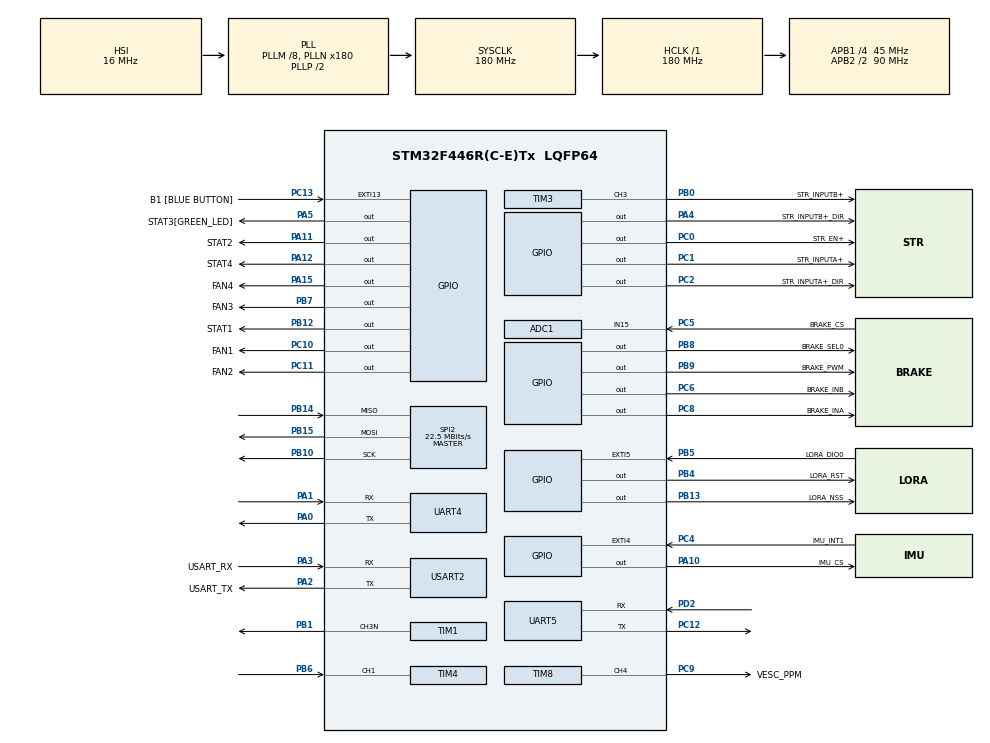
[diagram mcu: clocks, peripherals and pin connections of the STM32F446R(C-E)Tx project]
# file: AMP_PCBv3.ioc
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ADC1.Channel-0\#ChannelRegularConversion=ADC_CHANNEL_15
ADC1.NbrOfConversionFlag=1
ADC1.Rank-0\#ChannelRegularConversion=1
ADC1.SamplingTime-0\#ChannelRegularConversion=ADC_SAMPLETIME_3CYCLES
ADC1.master=1
Dma.Request0=USART2_TX
Dma.Request1=UART4_TX
Dma.Request2=UART4_RX
Dma.Request3=USART2_RX
Dma.Request4=TIM1_CH3
Dma.TIM1_CH3.4.Direction=DMA_MEMORY_TO_PERIPH
Dma.TIM1_CH3.4.FIFOMode=DMA_FIFOMODE_DISABLE
Dma.TIM1_CH3.4.Instance=DMA2_Stream6
Dma.TIM1_CH3.4.MemDataAlignment=DMA_MDATAALIGN_HALFWORD
Dma.TIM1_CH3.4.MemInc=DMA_MINC_ENABLE
Dma.TIM1_CH3.4.Mode=DMA_CIRCULAR
Dma.TIM1_CH3.4.PeriphDataAlignment=DMA_PDATAALIGN_HALFWORD
Dma.TIM1_CH3.4.PeriphInc=DMA_PINC_DISABLE
Dma.TIM1_CH3.4.Priority=DMA_PRIORITY_LOW
Dma.UART4_RX.2.Direction=DMA_PERIPH_TO_MEMORY
Dma.UART4_RX.2.FIFOMode=DMA_FIFOMODE_DISABLE
Dma.UART4_RX.2.Instance=DMA1_Stream2
Dma.UART4_RX.2.MemDataAlignment=DMA_MDATAALIGN_BYTE
Dma.UART4_RX.2.MemInc=DMA_MINC_ENABLE
Dma.UART4_RX.2.Mode=DMA_NORMAL
Dma.UART4_RX.2.PeriphDataAlignment=DMA_PDATAALIGN_BYTE
Dma.UART4_RX.2.PeriphInc=DMA_PINC_DISABLE
Dma.UART4_RX.2.Priority=DMA_PRIORITY_LOW
Dma.UART4_TX.1.Direction=DMA_MEMORY_TO_PERIPH
Dma.UART4_TX.1.FIFOMode=DMA_FIFOMODE_DISABLE
Dma.UART4_TX.1.Instance=DMA1_Stream4
Dma.UART4_TX.1.MemDataAlignment=DMA_MDATAALIGN_BYTE
Dma.UART4_TX.1.MemInc=DMA_MINC_ENABLE
Dma.UART4_TX.1.Mode=DMA_NORMAL
Dma.UART4_TX.1.PeriphDataAlignment=DMA_PDATAALIGN_BYTE
Dma.UART4_TX.1.PeriphInc=DMA_PINC_DISABLE
Dma.UART4_TX.1.Priority=DMA_PRIORITY_LOW
Dma.USART2_RX.3.Direction=DMA_PERIPH_TO_MEMORY
Dma.USART2_RX.3.FIFOMode=DMA_FIFOMODE_DISABLE
Dma.USART2_RX.3.Instance=DMA1_Stream5
Dma.USART2_RX.3.MemDataAlignment=DMA_MDATAALIGN_BYTE
Dma.USART2_RX.3.MemInc=DMA_MINC_ENABLE
Dma.USART2_RX.3.Mode=DMA_NORMAL
Dma.USART2_RX.3.PeriphDataAlignment=DMA_PDATAALIGN_BYTE
Dma.USART2_RX.3.PeriphInc=DMA_PINC_DISABLE
Dma.USART2_RX.3.Priority=DMA_PRIORITY_LOW
Dma.USART2_TX.0.Direction=DMA_MEMORY_TO_PERIPH
Dma.USART2_TX.0.FIFOMode=DMA_FIFOMODE_DISABLE
Dma.USART2_TX.0.Instance=DMA1_Stream6
Dma.USART2_TX.0.MemDataAlignment=DMA_MDATAALIGN_BYTE
Dma.USART2_TX.0.MemInc=DMA_MINC_ENABLE
Dma.USART2_TX.0.Mode=DMA_NORMAL
Dma.USART2_TX.0.PeriphDataAlignment=DMA_PDATAALIGN_BYTE
Dma.USART2_TX.0.PeriphInc=DMA_PINC_DISABLE
Dma.USART2_TX.0.Priority=DMA_PRIORITY_LOW
Mcu.Family=STM32F4
Mcu.Name=STM32F446R(C-E)Tx
Mcu.Package=LQFP64
NVIC.DMA1_Stream2_IRQn=true\:0\:0\:false\:false\:true\:false\:true\:true
NVIC.DMA1_Stream4_IRQn=true\:0\:0\:false\:false\:true\:false\:true\:true
NVIC.DMA1_Stream5_IRQn=true\:0\:0\:false\:false\:true\:false\:true\:true
NVIC.DMA1_Stream6_IRQn=true\:0\:0\:false\:false\:true\:false\:true\:true
NVIC.DMA2_Stream6_IRQn=true\:0\:0\:false\:false\:true\:false\:true\:true
NVIC.EXTI4_IRQn=true\:0\:0\:false\:false\:true\:true\:true\:true
NVIC.EXTI9_5_IRQn=true\:0\:0\:false\:false\:true\:true\:true\:true
NVIC.PriorityGroup=NVIC_PRIORITYGROUP_0
NVIC.TIM6_DAC_IRQn=true\:0\:0\:false\:false\:true\:true\:true\:true
NVIC.TIM7_IRQn=true\:0\:0\:false\:false\:true\:true\:true\:true
NVIC.UART4_IRQn=true\:0\:0\:false\:false\:true\:true\:true\:true
NVIC.USART2_IRQn=true\:0\:0\:false\:false\:true\:true\:true\:true
PA0-WKUP.Mode=Asynchronous
PA0-WKUP.Signal=UART4_TX
PA1.Mode=Asynchronous
PA1.Signal=UART4_RX
PA10.GPIO_Label=IMU_CS
PA10.Signal=GPIO_Output
PA11.GPIO_Label=STAT2
PA11.Signal=GPIO_Output
PA12.GPIO_Label=STAT4
PA12.Signal=GPIO_Output
PA13.GPIO_Label=TMS
PA13.Mode=Serial_Wire
PA13.Signal=SYS_JTMS-SWDIO
PA14.GPIO_Label=TCK
PA14.Mode=Serial_Wire
PA14.Signal=SYS_JTCK-SWCLK
PA15.GPIO_Label=FAN4
PA15.Signal=GPIO_Output
PA2.GPIO_Label=USART_TX
PA2.Mode=Asynchronous
PA2.Signal=USART2_TX
PA3.GPIO_Label=USART_RX
PA3.Mode=Asynchronous
PA3.Signal=USART2_RX
PA4.GPIO_Label=STR_INPUTB+_DIR
PA4.Signal=GPIO_Output
PA5.GPIO_Label=STAT3[GREEN_LED]
PA5.Signal=GPIO_Output
PB0.GPIO_Label=STR_INPUTB+
PB0.Signal=S_TIM3_CH3
PB1.Mode=PWM Generation3 CH3N
PB1.Signal=TIM1_CH3N
PB10.Mode=Full_Duplex_Master
PB10.Signal=SPI2_SCK
PB12.GPIO_Label=STAT1
PB12.Signal=GPIO_Output
PB13.GPIO_Label=LORA_NSS
PB13.Signal=GPIO_Output
PB14.Mode=Full_Duplex_Master
PB14.Signal=SPI2_MISO
PB15.Mode=Full_Duplex_Master
PB15.Signal=SPI2_MOSI
PB3.GPIO_Label=SWO
PB3.Signal=SYS_JTDO-SWO
PB4.GPIO_Label=LORA_RST
PB4.Signal=GPIO_Output
PB5.GPIO_Label=LORA_DIO0
PB5.Signal=GPXTI5
PB6.Signal=S_TIM4_CH1
PB7.GPIO_Label=FAN3
PB7.Signal=GPIO_Output
PB8.GPIO_Label=BRAKE_SEL0
PB8.Signal=GPIO_Output
PB9.GPIO_Label=BRAKE_PWM
PB9.Signal=GPIO_Output
PC0.GPIO_Label=STR_EN+
PC0.Signal=GPIO_Output
PC1.GPIO_Label=STR_INPUTA+
PC1.Signal=GPIO_Output
PC10.GPIO_Label=FAN1
PC10.Signal=GPIO_Output
PC11.GPIO_Label=FAN2
PC11.Signal=GPIO_Output
PC12.Mode=Asynchronous
PC12.Signal=UART5_TX
PC13.GPIO_Label=B1 [BLUE BUTTON]
PC13.GPIO_ModeDefaultEXTI=GPIO_MODE_IT_FALLING
PC13.Signal=GPXTI13
PC14-OSC32_IN.Mode=LSE-External-Oscillator
PC14-OSC32_IN.Signal=RCC_OSC32_IN
PC15-OSC32_OUT.Mode=LSE-External-Oscillator
PC15-OSC32_OUT.Signal=RCC_OSC32_OUT
PC2.GPIO_Label=STR_INPUTA+_DIR
PC2.Signal=GPIO_Output
PC4.GPIO_Label=IMU_INT1
PC4.Signal=GPXTI4
PC5.GPIO_Label=BRAKE_CS
PC5.Signal=ADCx_IN15
PC6.GPIO_Label=BRAKE_INB
PC6.Signal=GPIO_Output
PC8.GPIO_Label=BRAKE_INA
PC8.Signal=GPIO_Output
PC9.GPIO_Label=VESC_PPM
PC9.Signal=S_TIM8_CH4
PD2.Mode=Asynchronous
PD2.Signal=UART5_RX
PH0-OSC_IN.Mode=HSE-External-Oscillator
PH0-OSC_IN.Signal=RCC_OSC_IN
PH1-OSC_OUT.Mode=HSE-External-Oscillator
PH1-OSC_OUT.Signal=RCC_OSC_OUT
ProjectManager.HeapSize=0x200
ProjectManager.StackSize=0x400
ProjectManager.TargetToolchain=STM32CubeIDE
RCC.48MHZClocksFreq_Value=84000000
RCC.AHBFreq_Value=180000000
RCC.APB1CLKDivider=RCC_HCLK_DIV4
RCC.APB1Freq_Value=45000000
RCC.APB1TimFreq_Value=90000000
RCC.APB2CLKDivider=RCC_HCLK_DIV2
RCC.APB2Freq_Value=90000000
RCC.APB2TimFreq_Value=180000000
RCC.CortexFreq_Value=180000000
RCC.FLatency-AdvancedSettings=FLASH_LATENCY_5
RCC.HCLKFreq_Value=180000000
RCC.HSE_VALUE=8000000
RCC.HSI_VALUE=16000000
RCC.PLLM=8
RCC.PLLN=180
RCC.SYSCLKFreq_VALUE=180000000
RCC.SYSCLKSource=RCC_SYSCLKSOURCE_PLLCLK
RCC.USBFreq_Value=180000000
RCC.VCOOutputFreq_Value=360000000
SH.ADCx_IN15.0=ADC1_IN15,IN15
SH.S_TIM3_CH3.0=TIM3_CH3,PWM Generation3 CH3
SH.S_TIM4_CH1.0=TIM4_CH1,Input_Capture1_from_TI1
SH.S_TIM8_CH4.0=TIM8_CH4,PWM Generation4 CH4
SPI2.CalculateBaudRate=22.5 MBits/s
SPI2.Direction=SPI_DIRECTION_2LINES
SPI2.Mode=SPI_MODE_MASTER
SPI2.VirtualType=VM_MASTER
TIM1.AutoReloadPreload=TIM_AUTORELOAD_PRELOAD_ENABLE
TIM1.Channel-PWM\ Generation3\ CH3N=TIM_CHANNEL_3
TIM1.Period=2
TIM1.Prescaler=74
TIM1.Pulse-PWM\ Generation3\ CH3N=1
TIM1.TIM_MasterOutputTrigger=TIM_TRGO_UPDATE
TIM3.AutoReloadPreload=TIM_AUTORELOAD_PRELOAD_ENABLE
TIM3.Channel-PWM\ Generation3\ CH3=TIM_CHANNEL_3
TIM3.Period=255
TIM3.Prescaler=702
TIM3.Pulse-PWM\ Generation3\ CH3=128
TIM3.TIM_MasterOutputTrigger=TIM_TRGO_UPDATE
TIM4.Channel-Input_Capture1_from_TI1=TIM_CHANNEL_1
TIM6.AutoReloadPreload=TIM_AUTORELOAD_PRELOAD_ENABLE
TIM6.Period=99
TIM6.Prescaler=8999
TIM6.TIM_MasterOutputTrigger=TIM_TRGO_RESET
TIM7.AutoReloadPreload=TIM_AUTORELOAD_PRELOAD_ENABLE
TIM7.Period=4999
TIM7.Prescaler=8999
TIM8.Channel-PWM\ Generation4\ CH4=TIM_CHANNEL_4
UART4.VirtualMode=Asynchronous
UART5.VirtualMode=Asynchronous
USART2.VirtualMode=VM_ASYNC
VP_TIM1_VS_ClockSourceINT.Mode=Internal
VP_TIM2_VS_ClockSourceINT.Mode=Internal
VP_TIM3_VS_ClockSourceINT.Mode=Internal
VP_TIM6_VS_ClockSourceINT.Mode=Enable_Timer
VP_TIM7_VS_ClockSourceINT.Mode=Enable_Timer
VP_TIM8_VS_ClockSourceINT.Mode=Internal
board=NUCLEO-F446RE

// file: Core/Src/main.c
/* USER CODE BEGIN Header */
/**
  ******************************************************************************
  * @file           : main.c
  * @brief          : Main program body
  ******************************************************************************
  * @attention
  *
  * Copyright (c) 2024 STMicroelectronics.
  * All rights reserved.
  *
  * This software is licensed under terms that can be found in the LICENSE file
  * in the root directory of this software component.
  * If no LICENSE file comes with this software, it is provided AS-IS.
  *
  ******************************************************************************
  */
/* USER CODE END Header */
#include "main.h"
#include "adc.h"
#include "dma.h"
#include "spi.h"
#include "tim.h"
#include "usart.h"
#include "gpio.h"

/* USER CODE BEGIN Includes */
#include "app_statemachine.h"
/* USER CODE END Includes */

void SystemClock_Config(void);

int main(void)
{

  /* MCU Configuration--------------------------------------------------------*/

  /* Reset of all peripherals, Initializes the Flash interface and the Systick. */
  HAL_Init();

  /* Configure the system clock */
  SystemClock_Config();

  /* Initialize all configured peripherals */
  MX_GPIO_Init();
  MX_DMA_Init();
  MX_USART2_UART_Init();
  MX_UART4_Init();
  MX_SPI2_Init();
  MX_TIM3_Init();
  MX_TIM8_Init();
  MX_UART5_Init();
  MX_TIM1_Init();
  MX_ADC1_Init();
  MX_TIM2_Init();
  MX_TIM6_Init();
  MX_TIM4_Init();
  MX_TIM7_Init();
  /* USER CODE BEGIN 2 */
  // disable timer interrupt for tick() to make sure init() function completes
  HAL_TIM_Base_Stop_IT(&htim6);
  // call init() function for state machine
  App_StateMachine_Init();
  // re-enable timer interrupt for tick()
  HAL_TIM_Base_Start_IT(&htim6);
  /* USER CODE END 2 */

  /* Infinite loop */
  while (1)
  {

  }
}

void SystemClock_Config(void)
{
  RCC_OscInitTypeDef RCC_OscInitStruct = {0};
  RCC_ClkInitTypeDef RCC_ClkInitStruct = {0};

  /** Configure the main internal regulator output voltage
  */
  __HAL_RCC_PWR_CLK_ENABLE();
  __HAL_PWR_VOLTAGESCALING_CONFIG(PWR_REGULATOR_VOLTAGE_SCALE1);

  /** Initializes the RCC Oscillators according to the specified parameters
  * in the RCC_OscInitTypeDef structure.
  */
  RCC_OscInitStruct.OscillatorType = RCC_OSCILLATORTYPE_HSI;
  RCC_OscInitStruct.HSIState = RCC_HSI_ON;
  RCC_OscInitStruct.HSICalibrationValue = RCC_HSICALIBRATION_DEFAULT;
  RCC_OscInitStruct.PLL.PLLState = RCC_PLL_ON;
  RCC_OscInitStruct.PLL.PLLSource = RCC_PLLSOURCE_HSI;
  RCC_OscInitStruct.PLL.PLLM = 8;
  RCC_OscInitStruct.PLL.PLLN = 180;
  RCC_OscInitStruct.PLL.PLLP = RCC_PLLP_DIV2;
  RCC_OscInitStruct.PLL.PLLQ = 2;
  RCC_OscInitStruct.PLL.PLLR = 2;
  if (HAL_RCC_OscConfig(&RCC_OscInitStruct) != HAL_OK)
  {
    Error_Handler();
  }

  /** Activate the Over-Drive mode
  */
  if (HAL_PWREx_EnableOverDrive() != HAL_OK)
  {
    Error_Handler();
  }

  /** Initializes the CPU, AHB and APB buses clocks
  */
  RCC_ClkInitStruct.ClockType = RCC_CLOCKTYPE_HCLK|RCC_CLOCKTYPE_SYSCLK
                              |RCC_CLOCKTYPE_PCLK1|RCC_CLOCKTYPE_PCLK2;
  RCC_ClkInitStruct.SYSCLKSource = RCC_SYSCLKSOURCE_PLLCLK;
  RCC_ClkInitStruct.AHBCLKDivider = RCC_SYSCLK_DIV1;
  RCC_ClkInitStruct.APB1CLKDivider = RCC_HCLK_DIV4;
  RCC_ClkInitStruct.APB2CLKDivider = RCC_HCLK_DIV2;

  if (HAL_RCC_ClockConfig(&RCC_ClkInitStruct, FLASH_LATENCY_5) != HAL_OK)
  {
    Error_Handler();
  }
}

void Error_Handler(void)
{
  __disable_irq();
  while (1)
  {
  }
}
